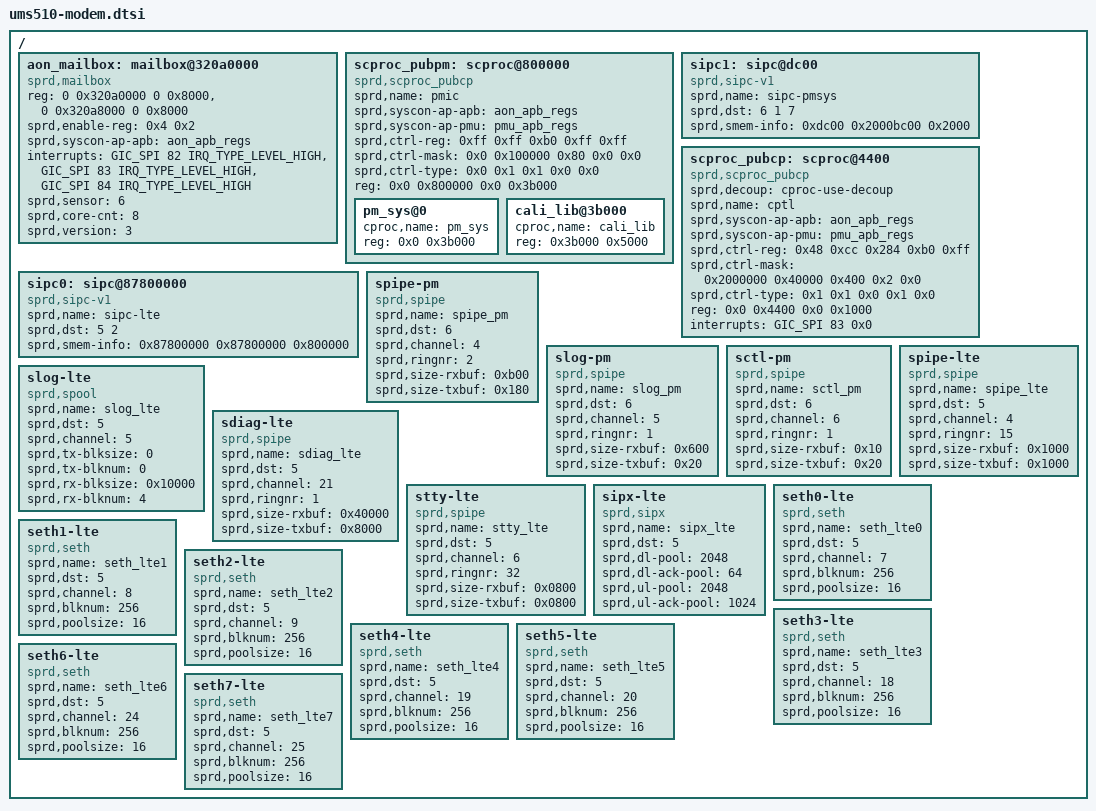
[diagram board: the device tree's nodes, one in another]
/*
 * Spreadtrum Sharkl5 modem board DTSI file
 * These dt is used for modem drivers
 *
 * Copyright (C) 2018, Spreadtrum Communications Inc.
 *
 * This file is licensed under a dual GPLv2 or X11 license.
 */

/ {
	aon_mailbox: mailbox@320a0000 {
		compatible = "sprd,mailbox";
		reg = <0 0x320a0000 0 0x8000>,
		      <0 0x320a8000 0 0x8000>;
		sprd,enable-reg = <0x4 0x2>;
		sprd,syscon-ap-apb = <&aon_apb_regs>;
		interrupts = <GIC_SPI 82 IRQ_TYPE_LEVEL_HIGH>,
			     <GIC_SPI 83 IRQ_TYPE_LEVEL_HIGH>,
			     <GIC_SPI 84 IRQ_TYPE_LEVEL_HIGH>;
		sprd,sensor = <6>;
		sprd,core-cnt = <8>;
		sprd,version = <3>;
	};

	scproc_pubpm: scproc@800000 {
		compatible = "sprd,scproc_pubcp";
		sprd,name = "pmic";
		sprd,syscon-ap-apb = <&aon_apb_regs>;
		sprd,syscon-ap-pmu = <&pmu_apb_regs>;
		sprd,ctrl-reg = <0xff 0xff 0xb0 0xff 0xff>;
		sprd,ctrl-mask = <0x0 0x100000 0x80 0x0 0x0>;
		sprd,ctrl-type = <0x0 0x1 0x1 0x0 0x0>;
		reg = <0x0 0x800000 0x0 0x3b000>;
		#address-cells = <1>;
		#size-cells = <1>;
		/* segnr=1 */
		ranges = <0x0 0x0 0x800000 0x3b000>,
				<0x3b000 0x0 0x83b000 0x5000>;
		pm_sys@0 {
			cproc,name = "pm_sys";
			reg = <0x0 0x3b000>;
		};

		cali_lib@3b000 {
			cproc,name = "cali_lib";
			reg = <0x3b000 0x5000>; /* <cali_lib_addr size> */
		};
	};

	sipc1: sipc@dc00 {
		compatible = "sprd,sipc-v1";
		sprd,name = "sipc-pmsys";
		sprd,dst = <6 1 7>; /* <dst core-id> */
		/* <ap-addr dst-maped-addr size> */
		sprd,smem-info = <0xdc00 0x2000bc00 0x2000>;
	};

	scproc_pubcp: scproc@4400 {
		compatible = "sprd,scproc_pubcp";
		sprd,decoup = "cproc-use-decoup";
		sprd,name = "cptl";
		sprd,syscon-ap-apb = <&aon_apb_regs>;
		sprd,syscon-ap-pmu = <&pmu_apb_regs>;
		sprd,ctrl-reg = <0x48 0xcc 0x284 0xb0 0xff>;
		sprd,ctrl-mask = <0x2000000 0x40000 0x400 0x2 0x0>;
		sprd,ctrl-type = <0x1 0x1 0x0 0x1 0x0>;
		reg = <0x0 0x4400 0x0 0x1000>;
		interrupts = <GIC_SPI 83 0x0>;
	};

	sipc0: sipc@87800000 {
		compatible = "sprd,sipc-v1";
		sprd,name = "sipc-lte";
		sprd,dst = <5 2>; /* <dst core-id> */
		/* <ap-addr dst-maped-addr size> */
		sprd,smem-info = <0x87800000 0x87800000 0x800000>;
	};

	spipe-pm {
		compatible = "sprd,spipe";
		sprd,name = "spipe_pm";
		sprd,dst = <6>;
		sprd,channel = <4>;
		sprd,ringnr = <2>;
		sprd,size-rxbuf = <0xb00>;
		sprd,size-txbuf = <0x180>;
	};

	slog-pm {
		compatible = "sprd,spipe";
		sprd,name = "slog_pm";
		sprd,dst = <6>;
		sprd,channel = <5>;
		sprd,ringnr = <1>;
		sprd,size-rxbuf = <0x600>;
		sprd,size-txbuf = <0x20>;
	};

	sctl-pm {
		compatible = "sprd,spipe";
		sprd,name = "sctl_pm";
		sprd,dst = <6>;
		sprd,channel = <6>;
		sprd,ringnr = <1>;
		sprd,size-rxbuf = <0x10>;
		sprd,size-txbuf = <0x20>;
	};

	spipe-lte {
		compatible = "sprd,spipe";
		sprd,name = "spipe_lte";
		sprd,dst = <5>;
		sprd,channel = <4>;
		sprd,ringnr = <15>;
		sprd,size-rxbuf = <0x1000>; /* 4*1024 */
		sprd,size-txbuf = <0x1000>; /* 4*1024 */
	};

	slog-lte {
		compatible = "sprd,spool";
		sprd,name = "slog_lte";
		sprd,dst = <5>;
		sprd,channel = <5>;
		sprd,tx-blksize = <0>;
		sprd,tx-blknum = <0>;
		sprd,rx-blksize = <0x10000>; /* 64k*/
		sprd,rx-blknum = <4>;
	};

	sdiag-lte {
		compatible = "sprd,spipe";
		sprd,name = "sdiag_lte";
		sprd,dst = <5>;
		sprd,channel = <21>;
		sprd,ringnr = <1>;
		sprd,size-rxbuf = <0x40000>; /* 256*1024*/
		sprd,size-txbuf = <0x8000>; /* 32*1024 */
	};

	stty-lte {
		compatible = "sprd,spipe";
		sprd,name = "stty_lte";
		sprd,dst = <5>;
		sprd,channel = <6>;
		sprd,ringnr = <32>;
		sprd,size-rxbuf = <0x0800>; /* 2*1024*/
		sprd,size-txbuf = <0x0800>; /* 2*1024 */
	};

	sipx-lte {
		compatible = "sprd,sipx";
		sprd,name = "sipx_lte";
		sprd,dst = <5>;
		sprd,dl-pool = <2048>;
		sprd,dl-ack-pool = <64>;
		sprd,ul-pool = <2048>;
		sprd,ul-ack-pool = <1024>;
	};

	seth0-lte {
		compatible = "sprd,seth";
		sprd,name = "seth_lte0";
		sprd,dst = <5>;
		sprd,channel = <7>;
		sprd,blknum = <256>;
		sprd,poolsize = <16>;
	};

	seth1-lte {
		compatible = "sprd,seth";
		sprd,name = "seth_lte1";
		sprd,dst = <5>;
		sprd,channel = <8>;
		sprd,blknum = <256>;
		sprd,poolsize = <16>;
	};

	seth2-lte {
		compatible = "sprd,seth";
		sprd,name = "seth_lte2";
		sprd,dst = <5>;
		sprd,channel = <9>;
		sprd,blknum = <256>;
		sprd,poolsize = <16>;
	};

	seth3-lte {
		compatible = "sprd,seth";
		sprd,name = "seth_lte3";
		sprd,dst = <5>;
		sprd,channel = <18>;
		sprd,blknum = <256>;
		sprd,poolsize = <16>;
	};

	seth4-lte {
		compatible = "sprd,seth";
		sprd,name = "seth_lte4";
		sprd,dst = <5>;
		sprd,channel = <19>;
		sprd,blknum = <256>;
		sprd,poolsize = <16>;
	};

	seth5-lte {
		compatible = "sprd,seth";
		sprd,name = "seth_lte5";
		sprd,dst = <5>;
		sprd,channel = <20>;
		sprd,blknum = <256>;
		sprd,poolsize = <16>;
	};

	seth6-lte {
		compatible = "sprd,seth";
		sprd,name = "seth_lte6";
		sprd,dst = <5>;
		sprd,channel = <24>;
		sprd,blknum = <256>;
		sprd,poolsize = <16>;
	};

	seth7-lte {
		compatible = "sprd,seth";
		sprd,name = "seth_lte7";
		sprd,dst = <5>;
		sprd,channel = <25>;
		sprd,blknum = <256>;
		sprd,poolsize = <16>;
	};
};

